# STMP3770 register map
Vendor: Freescale Semiconductor (NXP); Series: STMP37xx; File version: 1.0
CPU: other r0p0, little endian, no MPU, no FPU, 2 interrupt priority bits
Registers are 32-bit, read-write, reset 0x0 unless marked. A register's access mark holds for its fields unless they carry their own. Offsets are from the block's base; [hi:lo] are bit positions.

## AUDIOIN — 音频 ADC 输入(麦克风/线路输入采集与 DMA 控制)
Base 0x8004C000
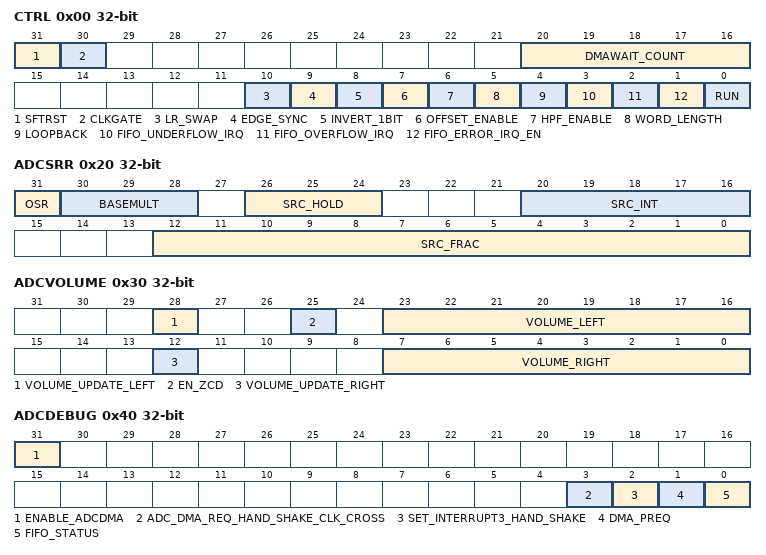
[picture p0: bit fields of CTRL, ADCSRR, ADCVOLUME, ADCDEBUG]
0x00 CTRL — AUDIOIN Control Register
  [31] SFTRST — AUDIOIN Module Soft Reset. Setting to 1 forces reset to DIGFILT portions that control audio input and gates clocks off. Must be cleared to 0 for normal operation.
  [30] CLKGATE — AUDIOIN Clock Gate Enable. When set to 1, gates off clocks to DIGFILT portions controlling input audio functions. Does not affect AUDIOOUT. Clear to 0 for normal operation.
  [20:16] DMAWAIT_COUNT — DMA Request Delay Count. Specifies number of APBX clock cycles (0-31) to delay before each DMA request. Acts as bandwidth throttle for DIGFILT.
  [10] LR_SWAP — Left/Right Input Channel Swap Enable. Setting to 1 swaps the left and right serial audio inputs from the ADC before CIC block processing.
  [9] EDGE_SYNC — Serial Input Clock Edge Sync Select. 0 = Rising edge, 1 = Falling edge for CIC filter data receive synchronization.
  [8] INVERT_1BIT — Invert Serial Audio Input Enable. When set, inverts the 1-bit serial input of both channels from the ADC sigma-delta modulator.
  [7] OFFSET_ENABLE — ADC Analog High-Pass Filter Offset Calculation Enable. When set, the HPF actively adjusts serial audio input removing DC offset. Requires HPF_ENABLE=1.
  [6] HPF_ENABLE — ADC High-Pass Filter Enable. When set, enables the ADC analog high-pass filter. Used with OFFSET_ENABLE for DC offset removal.
  [5] WORD_LENGTH — PCM Audio Bit Size Select. 0 = 32-bit PCM samples, 1 = 16-bit samples. 24-bit FIR output is sign-extended to 32 or truncated to 16.
  [4] LOOPBACK — AUDIOOUT-to-AUDIOIN Loopback Enable. Setting to 1 connects AUDIOOUT serial data to AUDIOIN CIC input, bypassing analog DAC and ADC.
  [3] FIFO_UNDERFLOW_IRQ — FIFO Underflow Interrupt Status Bit. Set by hardware on FIFO underflow. Cleared by writing 1 to SET/CLR address. IRQ issued if FIFO_ERROR_IRQ_EN=1.
  [2] FIFO_OVERFLOW_IRQ — FIFO Overflow Interrupt Status Bit. Set by hardware on FIFO overflow due to unserviced DMA request. Cleared by writing 1 to SET/CLR address.
  [1] FIFO_ERROR_IRQ_EN — FIFO Error Interrupt Enable. Set to 1 to enable interrupt request when FIFO overflow or underflow status bits are set.
  [0] RUN — AUDIOIN Enable. Setting to 1 starts data conversion; DMA request made after 8 words collected. Clearing to 0 stops conversion and sets CLKGATE.
0x10 STAT — AUDIOIN Status Register
  [31] ADC_PRESENT — AUDIOIN Functionality Present. Set to 1 in products that include AUDIOIN/ADC. If 0, the AUDIOIN/ADC is permanently disabled.
0x20 ADCSRR — AUDIOIN Sample Rate Register
  [31] OSR — AUDIOIN Oversample Rate (read-only). 0x0 = 6 MHz, 0x1 = 12 MHz. Fixed at 6 MHz for STMP3770.
    0=OSR6; 1=OSR12
  [30:28] BASEMULT — Base Sample Rate Multiplier. 0x1 = Single (48/44.1/32 kHz), 0x2 = Double (96/88.2/64 kHz), 0x4 = Quad (192/176.4/128 kHz).
    1=SINGLE_RATE; 2=DOUBLE_RATE; 4=QUAD_RATE
  [26:24] SRC_HOLD — Sample Rate Conversion Hold Factor. Used to generate half/quarter sample rates. Equation: output_sample_rate = (6e6 * BASEMULT) / (SRC_INT.SRC_FRAC * 8 * (SRC_HOLD+1)).
  [20:16] SRC_INT — Sample Rate Conversion Integer Factor. Integer portion of divide term. Reset 0x11. Used in sample rate equation.
  [12:0] SRC_FRAC — Sample Rate Conversion Fraction Factor. Fractional portion of divide term. Reset 0x37. Used in sample rate equation.
0x30 ADCVOLUME — AUDIOIN Volume Register
  [28] VOLUME_UPDATE_LEFT — Left Channel Volume Update Pending. Set by hardware when volume update is pending (waiting on zero-crossing on left channel). Not used when EN_ZCD=0.
  [25] EN_ZCD — Enable Zero-Cross Detect. When enabled, volume changes are applied only on zero-crossing. When disabled, changes take effect immediately.
  [23:16] VOLUME_LEFT — Left Channel Volume Setting. Range -0.5 dB (0xFE reset) to -100 dB (0x37). Each increment = +0.5 dB. Values 0x00-0x37 = -100 dB. 0xFF reserved.
  [12] VOLUME_UPDATE_RIGHT — Right Channel Volume Update Pending. Set by hardware when volume update is pending (waiting on zero-crossing on right channel). Not used when EN_ZCD=0.
  [7:0] VOLUME_RIGHT — Right Channel Volume Setting. Range -0.5 dB (0xFE reset) to -100 dB (0x37). Each increment = +0.5 dB. Values 0x00-0x37 = -100 dB. 0xFF reserved.
0x40 ADCDEBUG — AUDIOIN Debug Register
  [31] ENABLE_ADCDMA — AUDIOIN Digital Path Test Enable. For debug only. Causes serial audio data to bypass CIC block and transfer via AUDIOOUT DMA Channel 1.
  [3] ADC_DMA_REQ_HAND_SHAKE_CLK_CROSS — DMA Request Sync Status. Reflects state of second flop in the sync chain for AUDIOIN DMA request (24 MHz to APBX clock domain). Test only.
  [2] SET_INTERRUPT3_HAND_SHAKE — Interrupt[3] Status. Reflects APBX interface state machine internal interrupt[3] for DigFilt DMA channel priority. Test only.
  [1] DMA_PREQ — DMA Request Status. Reflects AUDIOIN DMA request signal state. Can be polled to manually move samples when DMA channel not used.
  [0] FIFO_STATUS — FIFO Status. Set when AUDIOIN FIFO contains any valid data. Cleared when FIFO is empty.
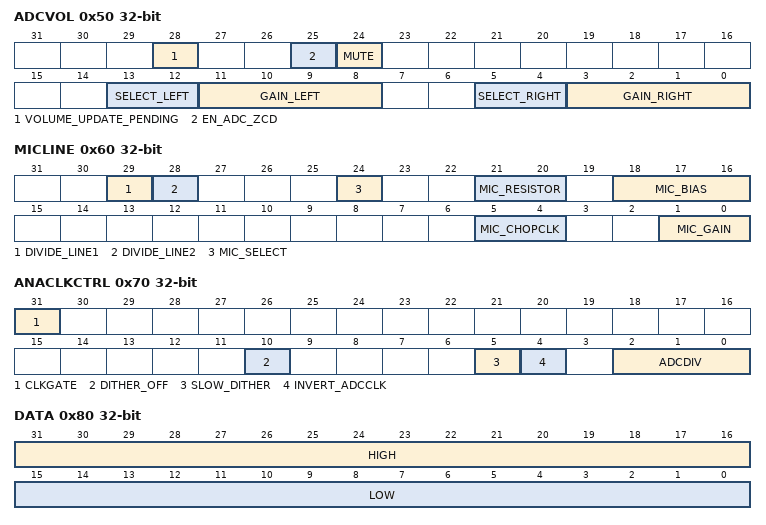
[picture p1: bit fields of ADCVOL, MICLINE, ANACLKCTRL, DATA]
0x50 ADCVOL — ADC Mux Volume and Select Control Register
  [28] VOLUME_UPDATE_PENDING — Volume Update Pending. Set when ADC left or right volume update is pending (waiting on zero-crossing). Cleared when both gains are applied.
  [25] EN_ADC_ZCD — Enable Zero-Cross Detect for ADC Amplifier.
  [24] MUTE — ADC Mute. 0 = Unmute, 1 = Mute. When set, mutes both left and right channel analog inputs.
  [13:12] SELECT_LEFT — ADC Left Channel Input Source Select. 00 = Microphone, 01 = Line1, 10 = Headphone, 11 = Reserved.
  [11:8] GAIN_LEFT — Left Channel ADC Gain. Each increment = 1.5 dB. 0x0 = 0 dB, 0x1 = 1.5 dB, ... up to 0xF = 22.5 dB.
  [5:4] SELECT_RIGHT — ADC Right Channel Input Source Select. 00 = Microphone, 01 = Line1, 10 = Headphone, 11 = Reserved.
  [3:0] GAIN_RIGHT — Right Channel ADC Gain. Each increment = 1.5 dB. 0x0 = 0 dB, 0x1 = 1.5 dB, ... up to 0xF = 22.5 dB.
0x60 MICLINE — Microphone and Line Control Register
  [29] DIVIDE_LINE1 — Attenuate Line1 Input. With 10K external series resistor, attenuates Line1 by 9.5 dB (+/-1.5 dB) for 2-Vrms input. Affects both channels of ADC and headphone.
  [28] DIVIDE_LINE2 — 线路输入2分压控制。
  [24] MIC_SELECT — Microphone Bias Pin Select. When MIC_RESISTOR enabled, selects Micbias voltage reference pin source. 0 = LRADC0, 1 = LRADC1.
  [21:20] MIC_RESISTOR — Microphone Bias Resistor Select. 00 = Off, 01 = 2 KOhm, 10 = 4 KOhm, 11 = 8 KOhm. ADC block must be powered on before Micbias.
  [18:16] MIC_BIAS — Microphone Bias Voltage Select. 0 = 1.21 V, 1 = 1.46 V, up to 7 = 2.96 V (0.25 V increments).
  [5:4] MIC_CHOPCLK — Microphone Amplifier Chopping Clock. 00 = Disabled, 01 = 192 kHz, 10 = 96 kHz, 11 = 48 kHz.
  [1:0] MIC_GAIN — Microphone Gain. 00 = 0 dB, 01 = 20 dB, 10 = 30 dB, 11 = 40 dB.
0x70 ANACLKCTRL — Analog Clock Control Register
  [31] CLKGATE — Analog Clock Gate. Set to gate the clocks for the ADC converter and associated digital filter.
  [10] DITHER_OFF — ADC Dither Disable. When set, dither is disabled within the ADC.
  [5] SLOW_DITHER — Slow Dither. When dither enabled (DITHER_OFF=0) and this bit set, ADC input signal dithering is slowed to half rate.
  [4] INVERT_ADCCLK — ADC Clock Invert. Set to invert ADC_CLK for the sigma-delta converter and associated digital filters.
  [2:0] ADCDIV — ADC Analog Clock Divider. Selects oversampling clock rate: 000=6 MHz, 001=4 MHz, 010/100=3 MHz, 011/101=2 MHz, 110=1.5 MHz, 111=1 MHz.
0x80 DATA — AUDIOIN Read Data Register
  [31:16] HIGH — Right Sample or Sample High Half-Word. 16-bit mode: right channel sample. 32-bit mode: most significant 16 bits of sample.
  [15:0] LOW — Left Sample or Sample Low Half-Word. 16-bit mode: left channel sample. 32-bit mode: least significant 16 bits of sample.
